VERSION ""

NS_ :

BS_:

BU_:

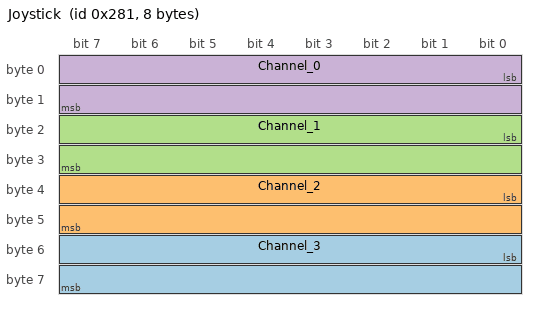
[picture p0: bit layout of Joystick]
BO_ 641 Joystick: 8 Vector__XXX
 SG_ Channel_3 : 48|16@1+ (1,0) [0|0] "" Vector__XXX
 SG_ Channel_2 : 32|16@1+ (1,0) [0|0] "" Vector__XXX
 SG_ Channel_1 : 16|16@1+ (1,0) [0|0] "" Vector__XXX
 SG_ Channel_0 : 0|16@1+ (1,0) [0|0] "" Vector__XXX
